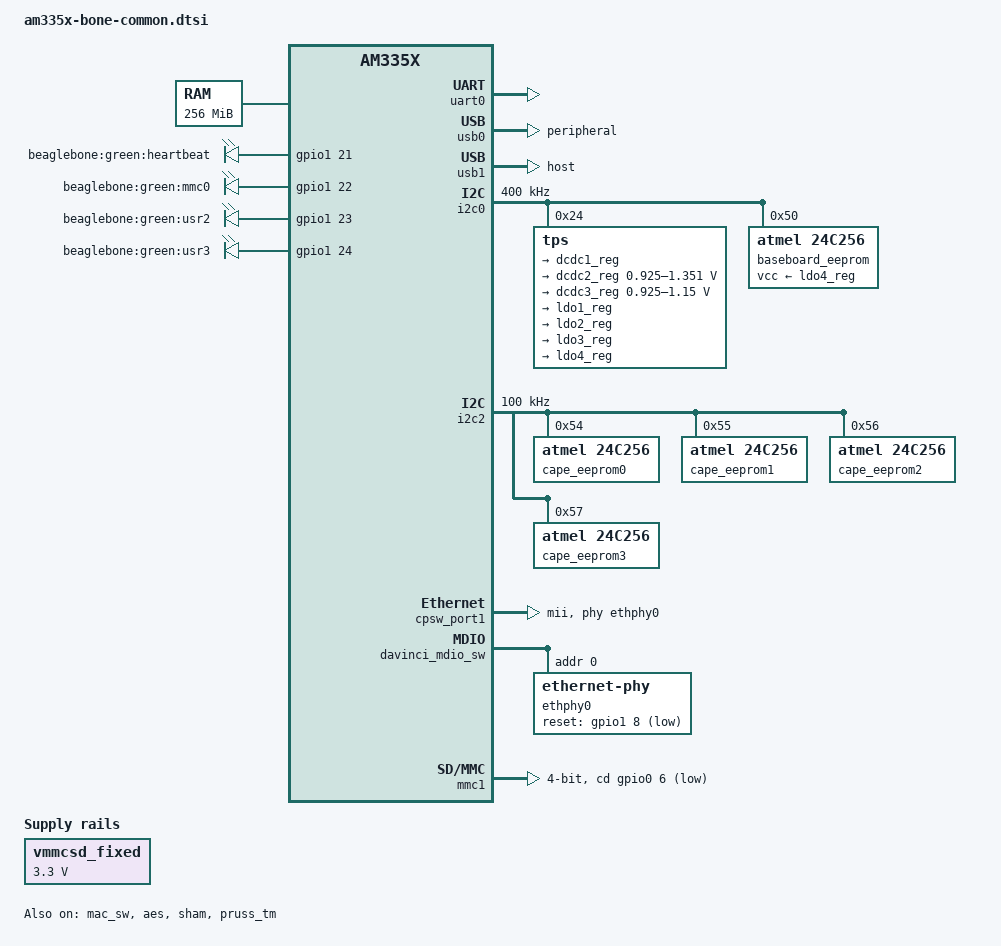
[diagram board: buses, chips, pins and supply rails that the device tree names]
/ {
	cpus {
		cpu@0 {
			cpu0-supply = <&dcdc2_reg>;
		};
	};
	memory@80000000 {
		device_type = "memory";
		reg = <0x80000000 0x10000000>;  
	};
	chosen {
		stdout-path = &uart0;
	};
	leds {
		pinctrl-names = "default";
		pinctrl-0 = <&user_leds_s0>;
		compatible = "gpio-leds";
		led2 {
			label = "beaglebone:green:heartbeat";
			gpios = <&gpio1 21 GPIO_ACTIVE_HIGH>;
			linux,default-trigger = "heartbeat";
			default-state = "off";
		};
		led3 {
			label = "beaglebone:green:mmc0";
			gpios = <&gpio1 22 GPIO_ACTIVE_HIGH>;
			linux,default-trigger = "mmc0";
			default-state = "off";
		};
		led4 {
			label = "beaglebone:green:usr2";
			gpios = <&gpio1 23 GPIO_ACTIVE_HIGH>;
			linux,default-trigger = "cpu0";
			default-state = "off";
		};
		led5 {
			label = "beaglebone:green:usr3";
			gpios = <&gpio1 24 GPIO_ACTIVE_HIGH>;
			linux,default-trigger = "mmc1";
			default-state = "off";
		};
	};
	vmmcsd_fixed: fixedregulator0 {
		compatible = "regulator-fixed";
		regulator-name = "vmmcsd_fixed";
		regulator-min-microvolt = <3300000>;
		regulator-max-microvolt = <3300000>;
	};
};
&am33xx_pinmux {
	pinctrl-names = "default";
	pinctrl-0 = <&clkout2_pin>;
	user_leds_s0: user-leds-s0-pins {
		pinctrl-single,pins = <
			AM33XX_PADCONF(AM335X_PIN_GPMC_A5, PIN_OUTPUT_PULLDOWN, MUX_MODE7)	 
			AM33XX_PADCONF(AM335X_PIN_GPMC_A6, PIN_OUTPUT_PULLUP, MUX_MODE7)	 
			AM33XX_PADCONF(AM335X_PIN_GPMC_A7, PIN_OUTPUT_PULLDOWN, MUX_MODE7)	 
			AM33XX_PADCONF(AM335X_PIN_GPMC_A8, PIN_OUTPUT_PULLUP, MUX_MODE7)	 
		>;
	};
	i2c0_pins: i2c0-pins {
		pinctrl-single,pins = <
			AM33XX_PADCONF(AM335X_PIN_I2C0_SDA, PIN_INPUT_PULLUP, MUX_MODE0)	 
			AM33XX_PADCONF(AM335X_PIN_I2C0_SCL, PIN_INPUT_PULLUP, MUX_MODE0)	 
		>;
	};
	i2c2_pins: i2c2-pins {
		pinctrl-single,pins = <
			AM33XX_PADCONF(AM335X_PIN_UART1_CTSN, PIN_INPUT_PULLUP, MUX_MODE3)	 
			AM33XX_PADCONF(AM335X_PIN_UART1_RTSN, PIN_INPUT_PULLUP, MUX_MODE3)	 
		>;
	};
	uart0_pins: uart0-pins {
		pinctrl-single,pins = <
			AM33XX_PADCONF(AM335X_PIN_UART0_RXD, PIN_INPUT_PULLUP, MUX_MODE0)
			AM33XX_PADCONF(AM335X_PIN_UART0_TXD, PIN_OUTPUT_PULLDOWN, MUX_MODE0)
		>;
	};
	clkout2_pin: clkout2-pins {
		pinctrl-single,pins = <
			AM33XX_PADCONF(AM335X_PIN_XDMA_EVENT_INTR1, PIN_OUTPUT_PULLDOWN, MUX_MODE3)	 
		>;
	};
	cpsw_default: cpsw-default-pins {
		pinctrl-single,pins = <
			AM33XX_PADCONF(AM335X_PIN_MII1_RX_ER, PIN_INPUT_PULLUP, MUX_MODE0)
			AM33XX_PADCONF(AM335X_PIN_MII1_TX_EN, PIN_OUTPUT_PULLDOWN, MUX_MODE0)
			AM33XX_PADCONF(AM335X_PIN_MII1_RX_DV, PIN_INPUT_PULLUP, MUX_MODE0)
			AM33XX_PADCONF(AM335X_PIN_MII1_TXD3, PIN_OUTPUT_PULLDOWN, MUX_MODE0)
			AM33XX_PADCONF(AM335X_PIN_MII1_TXD2, PIN_OUTPUT_PULLDOWN, MUX_MODE0)
			AM33XX_PADCONF(AM335X_PIN_MII1_TXD1, PIN_OUTPUT_PULLDOWN, MUX_MODE0)
			AM33XX_PADCONF(AM335X_PIN_MII1_TXD0, PIN_OUTPUT_PULLDOWN, MUX_MODE0)
			AM33XX_PADCONF(AM335X_PIN_MII1_TX_CLK, PIN_INPUT_PULLUP, MUX_MODE0)
			AM33XX_PADCONF(AM335X_PIN_MII1_RX_CLK, PIN_INPUT_PULLUP, MUX_MODE0)
			AM33XX_PADCONF(AM335X_PIN_MII1_RXD3, PIN_INPUT_PULLUP, MUX_MODE0)
			AM33XX_PADCONF(AM335X_PIN_MII1_RXD2, PIN_INPUT_PULLUP, MUX_MODE0)
			AM33XX_PADCONF(AM335X_PIN_MII1_RXD1, PIN_INPUT_PULLUP, MUX_MODE0)
			AM33XX_PADCONF(AM335X_PIN_MII1_RXD0, PIN_INPUT_PULLUP, MUX_MODE0)
		>;
	};
	cpsw_sleep: cpsw-sleep-pins {
		pinctrl-single,pins = <
			AM33XX_PADCONF(AM335X_PIN_MII1_RX_ER, PIN_INPUT_PULLDOWN, MUX_MODE7)
			AM33XX_PADCONF(AM335X_PIN_MII1_TX_EN, PIN_INPUT_PULLDOWN, MUX_MODE7)
			AM33XX_PADCONF(AM335X_PIN_MII1_RX_DV, PIN_INPUT_PULLDOWN, MUX_MODE7)
			AM33XX_PADCONF(AM335X_PIN_MII1_TXD3, PIN_INPUT_PULLDOWN, MUX_MODE7)
			AM33XX_PADCONF(AM335X_PIN_MII1_TXD2, PIN_INPUT_PULLDOWN, MUX_MODE7)
			AM33XX_PADCONF(AM335X_PIN_MII1_TXD1, PIN_INPUT_PULLDOWN, MUX_MODE7)
			AM33XX_PADCONF(AM335X_PIN_MII1_TXD0, PIN_INPUT_PULLDOWN, MUX_MODE7)
			AM33XX_PADCONF(AM335X_PIN_MII1_TX_CLK, PIN_INPUT_PULLDOWN, MUX_MODE7)
			AM33XX_PADCONF(AM335X_PIN_MII1_RX_CLK, PIN_INPUT_PULLDOWN, MUX_MODE7)
			AM33XX_PADCONF(AM335X_PIN_MII1_RXD3, PIN_INPUT_PULLDOWN, MUX_MODE7)
			AM33XX_PADCONF(AM335X_PIN_MII1_RXD2, PIN_INPUT_PULLDOWN, MUX_MODE7)
			AM33XX_PADCONF(AM335X_PIN_MII1_RXD1, PIN_INPUT_PULLDOWN, MUX_MODE7)
			AM33XX_PADCONF(AM335X_PIN_MII1_RXD0, PIN_INPUT_PULLDOWN, MUX_MODE7)
		>;
	};
	davinci_mdio_default: davinci-mdio-default-pins {
		pinctrl-single,pins = <
			AM33XX_PADCONF(AM335X_PIN_MDIO, PIN_INPUT_PULLUP | SLEWCTRL_FAST, MUX_MODE0)
			AM33XX_PADCONF(AM335X_PIN_MDC, PIN_OUTPUT_PULLUP, MUX_MODE0)
			AM33XX_PADCONF(AM335X_PIN_UART0_CTSN, PIN_OUTPUT_PULLUP, MUX_MODE7)
		>;
	};
	davinci_mdio_sleep: davinci-mdio-sleep-pins {
		pinctrl-single,pins = <
			AM33XX_PADCONF(AM335X_PIN_MDIO, PIN_INPUT_PULLDOWN, MUX_MODE7)
			AM33XX_PADCONF(AM335X_PIN_MDC, PIN_INPUT_PULLDOWN, MUX_MODE7)
			AM33XX_PADCONF(AM335X_PIN_UART0_CTSN, PIN_INPUT_PULLDOWN, MUX_MODE7)
		>;
	};
	mmc1_pins: mmc1-pins {
		pinctrl-single,pins = <
			AM33XX_PADCONF(AM335X_PIN_SPI0_CS1, PIN_INPUT, MUX_MODE7)		 
			AM33XX_PADCONF(AM335X_PIN_MMC0_DAT0, PIN_INPUT_PULLUP, MUX_MODE0)
			AM33XX_PADCONF(AM335X_PIN_MMC0_DAT1, PIN_INPUT_PULLUP, MUX_MODE0)
			AM33XX_PADCONF(AM335X_PIN_MMC0_DAT2, PIN_INPUT_PULLUP, MUX_MODE0)
			AM33XX_PADCONF(AM335X_PIN_MMC0_DAT3, PIN_INPUT_PULLUP, MUX_MODE0)
			AM33XX_PADCONF(AM335X_PIN_MMC0_CMD, PIN_INPUT_PULLUP, MUX_MODE0)
			AM33XX_PADCONF(AM335X_PIN_MMC0_CLK, PIN_INPUT_PULLUP, MUX_MODE0)
		>;
	};
	emmc_pins: emmc-pins {
		pinctrl-single,pins = <
			AM33XX_PADCONF(AM335X_PIN_GPMC_CSN1, PIN_INPUT_PULLUP, MUX_MODE2)  
			AM33XX_PADCONF(AM335X_PIN_GPMC_CSN2, PIN_INPUT_PULLUP, MUX_MODE2)  
			AM33XX_PADCONF(AM335X_PIN_GPMC_AD0, PIN_INPUT_PULLUP, MUX_MODE1)  
			AM33XX_PADCONF(AM335X_PIN_GPMC_AD1, PIN_INPUT_PULLUP, MUX_MODE1)  
			AM33XX_PADCONF(AM335X_PIN_GPMC_AD2, PIN_INPUT_PULLUP, MUX_MODE1)  
			AM33XX_PADCONF(AM335X_PIN_GPMC_AD3, PIN_INPUT_PULLUP, MUX_MODE1)  
			AM33XX_PADCONF(AM335X_PIN_GPMC_AD4, PIN_INPUT_PULLUP, MUX_MODE1)  
			AM33XX_PADCONF(AM335X_PIN_GPMC_AD5, PIN_INPUT_PULLUP, MUX_MODE1)  
			AM33XX_PADCONF(AM335X_PIN_GPMC_AD6, PIN_INPUT_PULLUP, MUX_MODE1)  
			AM33XX_PADCONF(AM335X_PIN_GPMC_AD7, PIN_INPUT_PULLUP, MUX_MODE1)  
		>;
	};
};
&uart0 {
	pinctrl-names = "default";
	pinctrl-0 = <&uart0_pins>;
	status = "okay";
};
&usb0 {
	dr_mode = "peripheral";
	interrupts-extended = <&intc 18 &tps 0>;
	interrupt-names = "mc", "vbus";
};
&usb1 {
	dr_mode = "host";
};
&i2c0 {
	pinctrl-names = "default";
	pinctrl-0 = <&i2c0_pins>;
	status = "okay";
	clock-frequency = <400000>;
	tps: tps@24 {
		reg = <0x24>;
	};
	baseboard_eeprom: baseboard_eeprom@50 {
		compatible = "atmel,24c256";
		reg = <0x50>;
		vcc-supply = <&ldo4_reg>;
		#address-cells = <1>;
		#size-cells = <1>;
		baseboard_data: baseboard_data@0 {
			reg = <0 0x100>;
		};
	};
};
&i2c2 {
	pinctrl-names = "default";
	pinctrl-0 = <&i2c2_pins>;
	status = "okay";
	clock-frequency = <100000>;
	cape_eeprom0: cape_eeprom0@54 {
		compatible = "atmel,24c256";
		reg = <0x54>;
		#address-cells = <1>;
		#size-cells = <1>;
		cape0_data: cape_data@0 {
			reg = <0 0x100>;
		};
	};
	cape_eeprom1: cape_eeprom1@55 {
		compatible = "atmel,24c256";
		reg = <0x55>;
		#address-cells = <1>;
		#size-cells = <1>;
		cape1_data: cape_data@0 {
			reg = <0 0x100>;
		};
	};
	cape_eeprom2: cape_eeprom2@56 {
		compatible = "atmel,24c256";
		reg = <0x56>;
		#address-cells = <1>;
		#size-cells = <1>;
		cape2_data: cape_data@0 {
			reg = <0 0x100>;
		};
	};
	cape_eeprom3: cape_eeprom3@57 {
		compatible = "atmel,24c256";
		reg = <0x57>;
		#address-cells = <1>;
		#size-cells = <1>;
		cape3_data: cape_data@0 {
			reg = <0 0x100>;
		};
	};
};
/include/ "../../tps65217.dtsi"
&tps {
	interrupts = <7>;  
	interrupt-parent = <&intc>;
	ti,pmic-shutdown-controller;
	charger {
		status = "okay";
	};
	pwrbutton {
		status = "okay";
	};
	regulators {
		dcdc1_reg: regulator@0 {
			regulator-name = "vdds_dpr";
			regulator-always-on;
		};
		dcdc2_reg: regulator@1 {
			regulator-name = "vdd_mpu";
			regulator-min-microvolt = <925000>;
			regulator-max-microvolt = <1351500>;
			regulator-boot-on;
			regulator-always-on;
		};
		dcdc3_reg: regulator@2 {
			regulator-name = "vdd_core";
			regulator-min-microvolt = <925000>;
			regulator-max-microvolt = <1150000>;
			regulator-boot-on;
			regulator-always-on;
		};
		ldo1_reg: regulator@3 {
			regulator-name = "vio,vrtc,vdds";
			regulator-always-on;
		};
		ldo2_reg: regulator@4 {
			regulator-name = "vdd_3v3aux";
			regulator-always-on;
		};
		ldo3_reg: regulator@5 {
			regulator-name = "vdd_1v8";
			regulator-always-on;
		};
		ldo4_reg: regulator@6 {
			regulator-name = "vdd_3v3a";
			regulator-always-on;
		};
	};
};
&cpsw_port1 {
	phy-handle = <&ethphy0>;
	phy-mode = "mii";
	ti,dual-emac-pvid = <1>;
};
&cpsw_port2 {
	status = "disabled";
};
&mac_sw {
	pinctrl-names = "default", "sleep";
	pinctrl-0 = <&cpsw_default>;
	pinctrl-1 = <&cpsw_sleep>;
	status = "okay";
};
&davinci_mdio_sw {
	pinctrl-names = "default", "sleep";
	pinctrl-0 = <&davinci_mdio_default>;
	pinctrl-1 = <&davinci_mdio_sleep>;
	ethphy0: ethernet-phy@0 {
		reg = <0>;
		reset-gpios = <&gpio1 8 GPIO_ACTIVE_LOW>;
		reset-assert-us = <300>;
		reset-deassert-us = <6500>;
	};
};
&mmc1 {
	status = "okay";
	bus-width = <0x4>;
	pinctrl-names = "default";
	pinctrl-0 = <&mmc1_pins>;
	cd-gpios = <&gpio0 6 GPIO_ACTIVE_LOW>;
};
&aes {
	status = "okay";
};
&sham {
	status = "okay";
};
&rtc {
	clocks = <&clk_32768_ck>, <&clk_24mhz_clkctrl AM3_CLK_24MHZ_CLKDIV32K_CLKCTRL 0>;
	clock-names = "ext-clk", "int-clk";
	system-power-controller;
};
&pruss_tm {
	status = "okay";
};
&wkup_m3_ipc {
	firmware-name = "am335x-bone-scale-data.bin";
};
